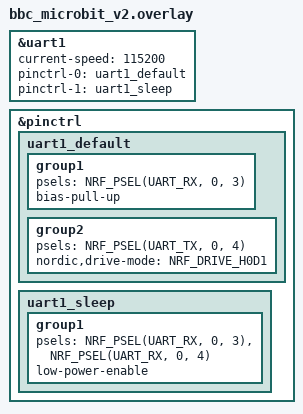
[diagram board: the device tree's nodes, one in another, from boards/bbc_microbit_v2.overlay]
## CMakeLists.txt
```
# SPDX-License-Identifier: Apache-2.0

cmake_minimum_required(VERSION 3.20.0)
find_package(Zephyr REQUIRED HINTS $ENV{ZEPHYR_BASE})
project(peripheral)

target_sources(app PRIVATE
  src/main.c
  src/temp.c
)
```

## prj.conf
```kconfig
# Increased stack due to settings API usage
CONFIG_SYSTEM_WORKQUEUE_STACK_SIZE=2048

CONFIG_BT=y
CONFIG_BT_DEBUG_LOG=y
CONFIG_BT_SMP=y
CONFIG_BT_SIGNING=y
CONFIG_BT_PERIPHERAL=y
CONFIG_BT_DIS=y
CONFIG_BT_ATT_PREPARE_COUNT=5
CONFIG_BT_PRIVACY=y
CONFIG_BT_DEVICE_NAME="Power meter"
CONFIG_BT_DEVICE_APPEARANCE=833
CONFIG_BT_DEVICE_NAME_DYNAMIC=n
CONFIG_BT_DEVICE_NAME_MAX=65

CONFIG_BT_BONDABLE=y

CONFIG_BT_KEYS_OVERWRITE_OLDEST=y
CONFIG_BT_SETTINGS=y
CONFIG_FLASH=y
CONFIG_FLASH_PAGE_LAYOUT=y
CONFIG_FLASH_MAP=y
CONFIG_NVS=y
CONFIG_SETTINGS=y

CONFIG_SENSOR=y
CONFIG_TEMP_NRF5=y

CONFIG_DISPLAY=y
CONFIG_MICROBIT_DISPLAY=y

CONFIG_NRFX_TIMER1=y

CONFIG_GPIO=y
CONFIG_NRFX_GPIOTE=y
CONFIG_NFCT_PINS_AS_GPIOS=y

# MAX 31820
CONFIG_W1=y
CONFIG_LOG=y
CONFIG_SENSOR_LOG_LEVEL_DBG=y
```

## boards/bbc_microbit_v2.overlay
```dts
/*
 * Copyright (c) 2022, Thomas Stranger
 *
 * SPDX-License-Identifier: Apache-2.0
 */

/*
 * Example configuration of a DS18b20 device on an Arduino serial bus, using
 * the zephyr-serial 1-Wire driver.
 * Open drain configuration allows communication by simply connecting the bus
 * line to the UART RX pin as well as the TX pin
 * An external pull-up should be added anyways.
 */

arduino_serial: &uart1 {
    status = "okay";
    current-speed = <115200>;
    pinctrl-0 = <&uart1_default>;
    pinctrl-1 = <&uart1_sleep>;
    pinctrl-names = "default", "sleep";
};

#include "serial_overlay.dtsi"

&pinctrl {
	uart1_default: uart1_default {
		group1 {
			psels = <NRF_PSEL(UART_RX, 0, 3)>;   /* P0.03 = edge P1 */
			bias-pull-up;
		};
		group2 {
			psels = <NRF_PSEL(UART_TX, 0, 4)>;   /* P0.04 = edge P2 */
			/* max. 5mA drive strength: */
			nordic,drive-mode = <NRF_DRIVE_H0D1>;
		};
	};

	uart1_sleep: uart1_sleep {
		group1 {
			psels = <NRF_PSEL(UART_RX, 0, 3)>,
                    <NRF_PSEL(UART_RX, 0, 4)>;
			low-power-enable;
		};
	};
};
```

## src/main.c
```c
/* main.c - Application main entry point */

/*
 * Copyright (c) 2015-2016 Intel Corporation
 *
 * SPDX-License-Identifier: Apache-2.0
 */

#include <zephyr/types.h>
#include <stddef.h>
#include <string.h>
#include <errno.h>
#include <zephyr/sys/printk.h>
#include <zephyr/sys/byteorder.h>
#include <zephyr/zephyr.h>

#include <zephyr/settings/settings.h>

#include <zephyr/display/mb_display.h>

#include <zephyr/bluetooth/bluetooth.h>
#include <zephyr/bluetooth/hci.h>
#include <zephyr/bluetooth/conn.h>
#include <zephyr/bluetooth/uuid.h>
#include <zephyr/bluetooth/gatt.h>

#include <zephyr/drivers/gpio.h>
#include <zephyr/drivers/counter.h>
#include <zephyr/drivers/sensor.h>

#include <zephyr/logging/log.h>
LOG_MODULE_REGISTER(main);

#include <nrfx_gpiote.h>
#include <nrfx_ppi.h>
#include <nrfx_timer.h>

#include "main.h"

#define SCROLL_SPEED 400

/* BLE */

static const struct bt_data ad[] = {
	BT_DATA_BYTES(BT_DATA_FLAGS, (BT_LE_AD_GENERAL | BT_LE_AD_NO_BREDR)),
	BT_DATA_BYTES(BT_DATA_UUID16_ALL,
		      BT_UUID_16_ENCODE(BT_UUID_ENVSENS_TEMPERATURE_VAL)),
};

static void connected(struct bt_conn *conn, uint8_t err)
{
	if (err) {
		printk("Connection failed (err 0x%02x)\n", err);
	} else {
		printk("Connected\n");
	}
}

static void disconnected(struct bt_conn *conn, uint8_t reason)
{
	printk("Disconnected (reason 0x%02x)\n", reason);
}

BT_CONN_CB_DEFINE(conn_callbacks) = {
	.connected = connected,
	.disconnected = disconnected,
};

static void bt_ready(void)
{
	int err;

	printk("Bluetooth initialized\n");

	if (IS_ENABLED(CONFIG_SETTINGS)) {
		settings_load();
	}

	err = bt_le_adv_start(BT_LE_ADV_CONN_NAME, ad, ARRAY_SIZE(ad), NULL, 0);
	if (err) {
		printk("Advertising failed to start (err %d)\n", err);
		return;
	}

	printk("Advertising successfully started\n");
}

static void auth_passkey_display(struct bt_conn *conn, unsigned int passkey)
{
	char addr[BT_ADDR_LE_STR_LEN];

	bt_addr_le_to_str(bt_conn_get_dst(conn), addr, sizeof(addr));

	printk("Passkey for %s: %06u\n", addr, passkey);
}

static void auth_cancel(struct bt_conn *conn)
{
	char addr[BT_ADDR_LE_STR_LEN];

	bt_addr_le_to_str(bt_conn_get_dst(conn), addr, sizeof(addr));

	printk("Pairing cancelled: %s\n", addr);
}

static struct bt_conn_auth_cb auth_cb_display = {
	.passkey_display = auth_passkey_display,
	.passkey_entry = NULL,
	.cancel = auth_cancel,
};

/* BUTTONS */

#define SWITCH_PIN 12
static const struct gpio_dt_spec sw0_gpio = GPIO_DT_SPEC_GET(DT_ALIAS(sw0), gpios);
static const struct gpio_dt_spec sw1_gpio = GPIO_DT_SPEC_GET(DT_ALIAS(sw1), gpios);

static int64_t a_timestamp;
static int64_t b_timestamp;

static const struct device *gpio_dev;

void menu_engegar()
{
    gpio_pin_set(gpio_dev, SWITCH_PIN, 1);
}

void menu_apagar()
{
    gpio_pin_set(gpio_dev, SWITCH_PIN, 0);
}

void menu_boot()
{
    struct mb_display *disp = mb_display_get();

    mb_display_print(disp, MB_DISPLAY_MODE_DEFAULT | MB_DISPLAY_FLAG_LOOP,
            SCROLL_SPEED, "termo");
}

struct {
    const char *text;
    void (*callback)();
} options[] = {
    { "engegar", menu_engegar },
    { "apagar", menu_apagar },
    { "inici", menu_boot },
};

static int option;

#define NELEMS(a) sizeof(a)/sizeof(a[0])

static void button_pressed(const struct device *dev, struct gpio_callback *cb,
			   uint32_t pins)
{
	/* Filter out spurious presses */
	if (pins & BIT(sw0_gpio.pin)) {
		printk("A pressed\n");
		if (k_uptime_delta(&a_timestamp) < 100) {
			printk("Too quick A presses\n");
			return;
		}
	} else {
		printk("B pressed\n");
		if (k_uptime_delta(&b_timestamp) < 100) {
			printk("Too quick B presses\n");
			return;
		}
	}

	if (pins & BIT(sw0_gpio.pin)) {
        ++option;
        if (option >= NELEMS(options)) {
            option = 0;
        }
        struct mb_display *disp = mb_display_get();
        mb_display_print(disp, MB_DISPLAY_MODE_DEFAULT | MB_DISPLAY_FLAG_LOOP,
                SCROLL_SPEED, "%d %s", option, options[option].text);
	} else {
        options[option].callback();
	}
}

static void configure_buttons(void)
{
    static struct gpio_callback button_cb_data;

    /* since sw0_gpio.port == sw1_gpio.port, we only need to check ready once */
    if (!device_is_ready(sw0_gpio.port)) {
        printk("%s: device not ready.\n", sw0_gpio.port->name);
        return;
    }

    gpio_pin_configure_dt(&sw0_gpio, GPIO_INPUT);
    gpio_pin_configure_dt(&sw1_gpio, GPIO_INPUT);

    gpio_pin_configure_dt(&sw1_gpio, GPIO_INPUT);

    gpio_pin_interrupt_configure_dt(&sw0_gpio, GPIO_INT_EDGE_TO_ACTIVE);
    gpio_pin_interrupt_configure_dt(&sw1_gpio, GPIO_INT_EDGE_TO_ACTIVE);

    gpio_init_callback(&button_cb_data, button_pressed,
               BIT(sw0_gpio.pin) | BIT(sw1_gpio.pin));

    gpio_add_callback(sw0_gpio.port, &button_cb_data);

    /* Switch */
    gpio_dev = DEVICE_DT_GET(DT_NODELABEL(gpio0));
    if (!device_is_ready(sw0_gpio.port)) {
        printk("%s: device not ready.\n", gpio_dev->name);
        return;
    }

    gpio_pin_configure(gpio_dev, SWITCH_PIN, GPIO_OUTPUT_LOW | GPIO_ACTIVE_HIGH);
}

/* COUNT PULSES */

static nrfx_timer_t flowtimer_instance = NRFX_TIMER_INSTANCE(1);

static void timer_handler(nrf_timer_event_t event_type, void *p_context)
{
}

static void init_waterflow()
{
    nrfx_err_t err;

    uint8_t ppi_channel;
    uint8_t in_channel;

    /* Start the timer */
    static const nrfx_timer_config_t timer_config = {
        .frequency = NRF_TIMER_FREQ_31250Hz,
        .mode = NRF_TIMER_MODE_COUNTER,
        .bit_width = NRF_TIMER_BIT_WIDTH_32,
        .interrupt_priority = 0
    };

    err = nrfx_timer_init(&flowtimer_instance, &timer_config, timer_handler);
    if (err != NRFX_SUCCESS) {
        LOG_ERR("nrfx_timer_init error: 0x%08X", err);
        return;
    }

    nrfx_timer_enable(&flowtimer_instance);

    LOG_INF("timer initialized");

    /* GPIOTE */
    gpio_dev = DEVICE_DT_GET(DT_NODELABEL(gpio0));

    /* Initialize GPIOTE (the interrupt priority passed as the parameter
     * here is ignored, see nrfx_glue.h).
     */
    if (!nrfx_gpiote_is_init())
    {
        err = nrfx_gpiote_init(0);
        if (err != NRFX_SUCCESS) {
            LOG_ERR("nrfx_gpiote_init error: 0x%08X", err);
            return;
        }
    }

    err = nrfx_gpiote_channel_alloc(&in_channel);
    if (err != NRFX_SUCCESS) {
        LOG_ERR("Failed to allocate in_channel, error: 0x%08X", err);
        return;
    }

    /* Initialize input pin to generate event on high to low transition
     * (falling edge) and call button_handler()
     */
    static const nrfx_gpiote_input_config_t input_config = {
        .pull = NRF_GPIO_PIN_PULLUP,
    };
    const nrfx_gpiote_trigger_config_t trigger_config = {
        .trigger = NRFX_GPIOTE_TRIGGER_LOTOHI,
        .p_in_channel = &in_channel,
    };

#define INPUT_PIN 10 /* Edge connector pin 8, digital IO */
//#define INPUT_PIN 3 /* Edge connector pin 1, analog/digital IO */

    err = nrfx_gpiote_input_configure(INPUT_PIN,
                      &input_config,
                      &trigger_config,
                      NULL);

    if (err != NRFX_SUCCESS) {
        LOG_ERR("nrfx_gpiote_input_configure error: 0x%08X", err);
        return;
    }

    nrfx_gpiote_trigger_enable(INPUT_PIN, true);

    LOG_INF("nrfx_gpiote initialized");

    /* Allocate a PPI channel. */
    err = nrfx_ppi_channel_alloc(&ppi_channel);
    if (err != NRFX_SUCCESS) {
        LOG_ERR("nrfx_ppi_channel_alloc error: 0x%08X", err);
        return;
    }

    /* Configure endpoints of the channel so that the input pin event is
     * connected with the output pin OUT task. This means that each time
     * the button is pressed, the LED pin will be toggled.
     */
    err = nrfx_ppi_channel_assign(ppi_channel,
        nrfx_gpiote_in_event_addr_get(INPUT_PIN),
        nrfx_timer_task_address_get(&flowtimer_instance, NRF_TIMER_TASK_COUNT));

    if (err != NRFX_SUCCESS) {
        LOG_ERR("nrfx_ppi_channel_endpoints_setup error: 0x%08X", err);
        return;
    }

    /* Enable the channel. */
    nrfx_ppi_channel_enable(ppi_channel);


    LOG_INF("ppi initialized");
}

/*
 * Get a device structure from a devicetree node with compatible
 * "maxim,ds18b20". (If there are multiple, just pick one.)
 */
static const struct device *get_ds18b20_device(void)
{
    const struct device *dev = DEVICE_DT_GET_ANY(maxim_ds18b20);

    if (dev == NULL) {
        /* No such node, or the node does not have status "okay". */
        printk("\nError: no device found.\n");
        return NULL;
    }

    if (!device_is_ready(dev)) {
        printk("\nError: Device \"%s\" is not ready; "
               "check the driver initialization logs for errors.\n",
               dev->name);
        return NULL;
    }

    printk("Found device \"%s\", getting sensor data\n", dev->name);
    return dev;
}


void main(void)
{
	int err;

    configure_buttons();

    init_waterflow();

    menu_boot();

	err = bt_enable(NULL);
	if (err) {
		printk("Bluetooth init failed (err %d)\n", err);
		return;
	}

	bt_ready();

	bt_conn_auth_cb_register(&auth_cb_display);

    const struct device *dev = get_ds18b20_device();
    if (dev == NULL) {
        return;
    }


	/* Implement notification. At the moment there is no suitable way
	 * of starting delayed work so we do it here
	 */
	while (1) {
		k_sleep(K_SECONDS(1));
        printk("Counter: %d\n", nrfx_timer_capture(&flowtimer_instance, NRF_TIMER_CC_CHANNEL0));

        struct sensor_value temp;

        sensor_sample_fetch(dev);
        sensor_channel_get(dev, SENSOR_CHAN_AMBIENT_TEMP, &temp);

        printk("Temp: %d.%06d\n", temp.val1, temp.val2);
	}
}
```

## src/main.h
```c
#define BT_UUID_ENVSENS BT_UUID_DECLARE_16(0x181A)

#define BT_UUID_ENVSENS_TEMPERATURE_VAL 0x2A6E
#define BT_UUID_ENVSENS_TEMPERATURE BT_UUID_DECLARE_16(BT_UUID_ENVSENS_TEMPERATURE_VAL)
```

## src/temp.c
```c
/** @file
 *  @brief GATT Battery Service
 */

/*
 * Copyright (c) 2018 Nordic Semiconductor ASA
 * Copyright (c) 2016 Intel Corporation
 *
 * SPDX-License-Identifier: Apache-2.0
 */

#include <errno.h>
#include <zephyr/init.h>
#include <zephyr/sys/__assert.h>
#include <stdbool.h>
#include <zephyr/types.h>

#include <zephyr/bluetooth/bluetooth.h>
#include <zephyr/bluetooth/conn.h>
#include <zephyr/bluetooth/gatt.h>
#include <zephyr/bluetooth/uuid.h>
#include <zephyr/drivers/sensor.h>

#define LOG_LEVEL CONFIG_BT_BAS_LOG_LEVEL
#include <zephyr/logging/log.h>

#include "main.h"

LOG_MODULE_REGISTER(temp);

uint8_t bt_temp_get_temperature(void);

const struct device *temp_device;

static void temp_ccc_cfg_changed(const struct bt_gatt_attr *attr,
				       uint16_t value)
{
	ARG_UNUSED(attr);

	bool notif_enabled = (value == BT_GATT_CCC_NOTIFY);

	LOG_INF("TEMP Notifications %s", notif_enabled ? "enabled" : "disabled");
}

static ssize_t read_temp(struct bt_conn *conn,
			       const struct bt_gatt_attr *attr, void *buf,
			       uint16_t len, uint16_t offset)
{
	uint8_t lvl8 = bt_temp_get_temperature();

	return bt_gatt_attr_read(conn, attr, buf, len, offset, &lvl8,
				 sizeof(lvl8));
}

BT_GATT_SERVICE_DEFINE(temp,
	BT_GATT_PRIMARY_SERVICE(BT_UUID_ENVSENS),
	BT_GATT_CHARACTERISTIC(BT_UUID_ENVSENS_TEMPERATURE,
			       BT_GATT_CHRC_READ/* | BT_GATT_CHRC_NOTIFY*/,
			       BT_GATT_PERM_READ, read_temp, NULL,
			       &temp_device),
	BT_GATT_CCC(temp_ccc_cfg_changed,
		    BT_GATT_PERM_READ | BT_GATT_PERM_WRITE),
);

static int temp_init(const struct device *dev)
{
	ARG_UNUSED(dev);

    temp_device = DEVICE_DT_GET(DT_NODELABEL(temp));

    if (!device_is_ready(temp_device))
    {
        temp_device = 0;
        LOG_ERR("TEMP device not found");
    }
    LOG_INF("TEMP device initialised");

	return 0;
}

uint8_t bt_temp_get_temperature(void)
{
    if (temp_device)
    {
        sensor_sample_fetch(temp_device);
        struct sensor_value temp;
        sensor_channel_get(temp_device, SENSOR_CHAN_DIE_TEMP, &temp);

        return temp.val1;
    }
    return 0;
}

SYS_INIT(temp_init, APPLICATION, CONFIG_APPLICATION_INIT_PRIORITY);
```
